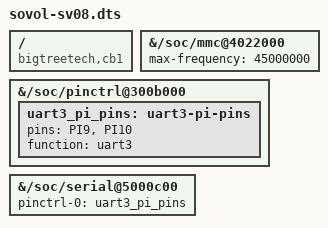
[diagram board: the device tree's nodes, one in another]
/dts-v1/;
/plugin/;

/*
 * Sovol SV08 on the Armbian BigTreeTech CB1 board profile.
 *
 * Differences vs the BTT CB1 device tree, taken from the vendor image:
 *   - eMMC (mmc2) clock capped at the vendor-validated 45 MHz
 *     (the Armbian CB1 dtb runs it at 150 MHz);
 *   - uart3 on PI9/PI10 enabled (toolboard port).
 *
 * PI9/PI10 mux to uart3 per the mainline sun50i-h616 pinctrl driver.
 */

/ {
	compatible = "bigtreetech,cb1", "allwinner,sun50i-h616";

	fragment@0 {
		target-path = "/soc/mmc@4022000";
		__overlay__ {
			max-frequency = <45000000>;
		};
	};

	fragment@1 {
		target-path = "/soc/pinctrl@300b000";
		__overlay__ {
			uart3_pi_pins: uart3-pi-pins {
				pins = "PI9", "PI10";
				function = "uart3";
			};
		};
	};

	fragment@2 {
		target-path = "/soc/serial@5000c00";
		__overlay__ {
			pinctrl-names = "default";
			pinctrl-0 = <&uart3_pi_pins>;
			status = "okay";
		};
	};
};
